# A31T21x register map
Vendor: ABOV Semiconductor Co., Ltd.; Series: A31T21x; File version: 1.0
CPU: CM0PLUS r0p1, little endian, no MPU, no FPU, VTOR, 2 interrupt priority bits
Registers are 32-bit, read-write, reset 0x0 unless marked. A register's access mark holds for its fields unless they carry their own. Offsets are from the block's base; [hi:lo] are bit positions.

## DMA0 — Direct Memory Access
Base 0x40000400
Same registers: DMA1 0x40000410, DMA2 0x40000420, DMA3 0x40000430
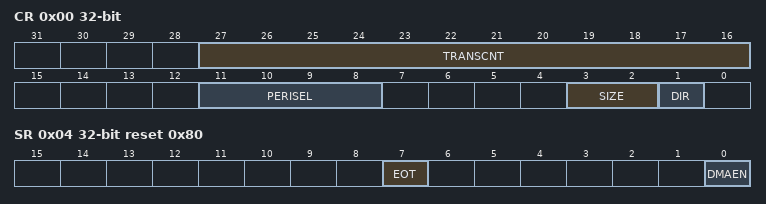
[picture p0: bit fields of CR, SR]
0x00 CR — DMA Channel n Control Register
  [27:16] TRANSCNT — Number of DMA transfer remained Required transfer number should be written before enable DMA transfer. 0 : DMA transfer is done. N : N transfers are remained.
  [11:8] PERISEL — Peripheral selction N : Associated peripheral selection. Refer to DMA Peripheral connection table
  [3:2] SIZE — Bus transfer size. 00: DMA transfer is byte size transfer 01: DMA transfer is half word size transfer 10: DMA transfer is word size transfer 11: Reserved
  [1] DIR — Select transfer direction. 0: Transfer direction is from memory to peripheral. (TX) 1: Transfer direction is from peripheral to memory. (RX)
0x04 SR reset 0x80 — DMA Channel n Status Register
  [7] EOT — End of transfer. 0: Data to be transferred is existing. TRANSCNT shows non zero value 1: All data is transferred. TRANSCNT shows now 0
  [0] DMAEN — DMA Enable 0: DMA is in stop or hold state 1: DMA is running or enabled
0x08 PAR reset 0x40000000 — DMA Channel n Peripheral Address
  [15:0] PAR — Target Peripheral address of transmit buffer or receive buffer. Address is fixed address when each transfer is done. If DIR is "0" this address is destination address of data transfer. If DIR is "1", this address is source address of data transfer.
0x0C MAR reset 0x20000000 — DMA Channel n Memory Address
  [15:0] MAR — Target memory address of data transfer. Address is automatically incremented according to SIZE bits when each transfer is done. If DIR is "0" this address is source address of data transfer. If DIR is "1", this address is destination address of data transfer.

## WDT — WATCH-DOG TIMER
Base 0x40001A00
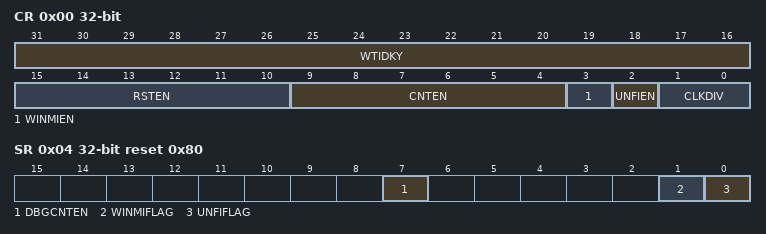
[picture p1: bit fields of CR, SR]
0x00 CR — Watch-dog Timer Control Register
  [31:16] WTIDKY wo — Write Identification Key. On writes, write 0x5A69 to these bits, otherwise the write is ignored.
  [15:10] RSTEN — Watch-dog Timer Reset Enable bits
  [9:4] CNTEN — Watch-dog Timer Counter Enable bits
  [3] WINMIEN — Watch-dog Timer Window Match Interrupt Enable bit
  [2] UNFIEN — Watch-dog Timer Underflow Interrupt Enable bit
  [1:0] CLKDIV — Watch-dog Timer Clock Divider bits, The clock which is selected by PPCLKSR[0]
0x04 SR reset 0x80 — Watch-dog Timer Status Register
  [7] DBGCNTEN — Watch-dog Timer Counter Enable bit. When the core is halted in the debug mode. Note: This bit is cleared to "0b" only by POR reset.
    0=RUN_CORE_HALTED (The watch-dog timer counter continues even if the core is halted.); 1=STOP_CORE_HALTED (The watch-dog timer counter is stopped when the core is halted.)
  [1] WINMIFLAG — Watch-dog Timer Window Match Interrupt Flag bit
    0=WDT_WDM_IF_CLR (No request occurred); 1=WDT_WDM_IF_SET (Request occurred, This bit is cleared to '0' when write '1'.)
  [0] UNFIFLAG — Watch-dog Timer Underflow Interrupt Flag bit
    0=WDT_UDF_IF_CLR (No request occurred); 1=WDT_UDF_IF_SET (Request occurred, This bit is cleared to '0' when write '1'.)
0x08 DR reset 0x3D09 — Watch-dog Timer Data Register
  [23:0] DATA — Watch-dog Timer Data bits. The range is 0x000000 to 0xFFFFFF.
0x0C CNT ro reset 0xFFF — Watch-dog Timer Counter Register
  [23:0] CNT — Watch-dog Timer Counter bits.
0x10 WINDR reset 0xFFFF — Watch-dog Timer Window Data Register (Note: Once any value is written to this window data register, the register can't be changed until a system reset.)
  [23:0] WDATA — Watch-dog Timer Window Data bits. The range is 0x000000 to 0xFFFFFF.
0x14 CNTR wo — Watch-dog Timer Counter Reload Register
  [7:0] CNTR — Watch-dog Timer Counter Reload bits.
    106=RELOAD_WDTDR (Reload the WDTDR value to watch-dog timer counter and re-start. (Automatically cleared to "0x00" after operation)); 0=UNLOAD_WDTDR (No effect)

## Notices in the file
Copyright (C) 2012-2014 ARM Limited. All rights reserved.
Purpose: System Viewer Description (SVD) Example (Schema Version 1.1)
This is a description of a none-existent and incomplete device
for demonstration purposes only.
Redistribution and use in source and binary forms, with or without
modification, are permitted provided that the following conditions are met:
- Redistributions of source code must retain the above copyright
notice, this list of conditions and the following disclaimer.
- Redistributions in binary form must reproduce the above copyright
notice, this list of conditions and the following disclaimer in the
documentation and/or other materials provided with the distribution.
- Neither the name of ARM nor the names of its contributors may be used
to endorse or promote products derived from this software without
specific prior written permission.
THIS SOFTWARE IS PROVIDED BY THE COPYRIGHT HOLDERS AND CONTRIBUTORS "AS IS"
AND ANY EXPRESS OR IMPLIED WARRANTIES, INCLUDING, BUT NOT LIMITED TO, THE
IMPLIED WARRANTIES OF MERCHANTABILITY AND FITNESS FOR A PARTICULAR PURPOSE
ARE DISCLAIMED. IN NO EVENT SHALL COPYRIGHT HOLDERS AND CONTRIBUTORS BE
LIABLE FOR ANY DIRECT, INDIRECT, INCIDENTAL, SPECIAL, EXEMPLARY, OR
CONSEQUENTIAL DAMAGES (INCLUDING, BUT NOT LIMITED TO, PROCUREMENT OF
SUBSTITUTE GOODS OR SERVICES; LOSS OF USE, DATA, OR PROFITS; OR BUSINESS
INTERRUPTION) HOWEVER CAUSED AND ON ANY THEORY OF LIABILITY, WHETHER IN
CONTRACT, STRICT LIABILITY, OR TORT (INCLUDING NEGLIGENCE OR OTHERWISE)
ARISING IN ANY WAY OUT OF THE USE OF THIS SOFTWARE, EVEN IF ADVISED OF THE
POSSIBILITY OF SUCH DAMAGE.
